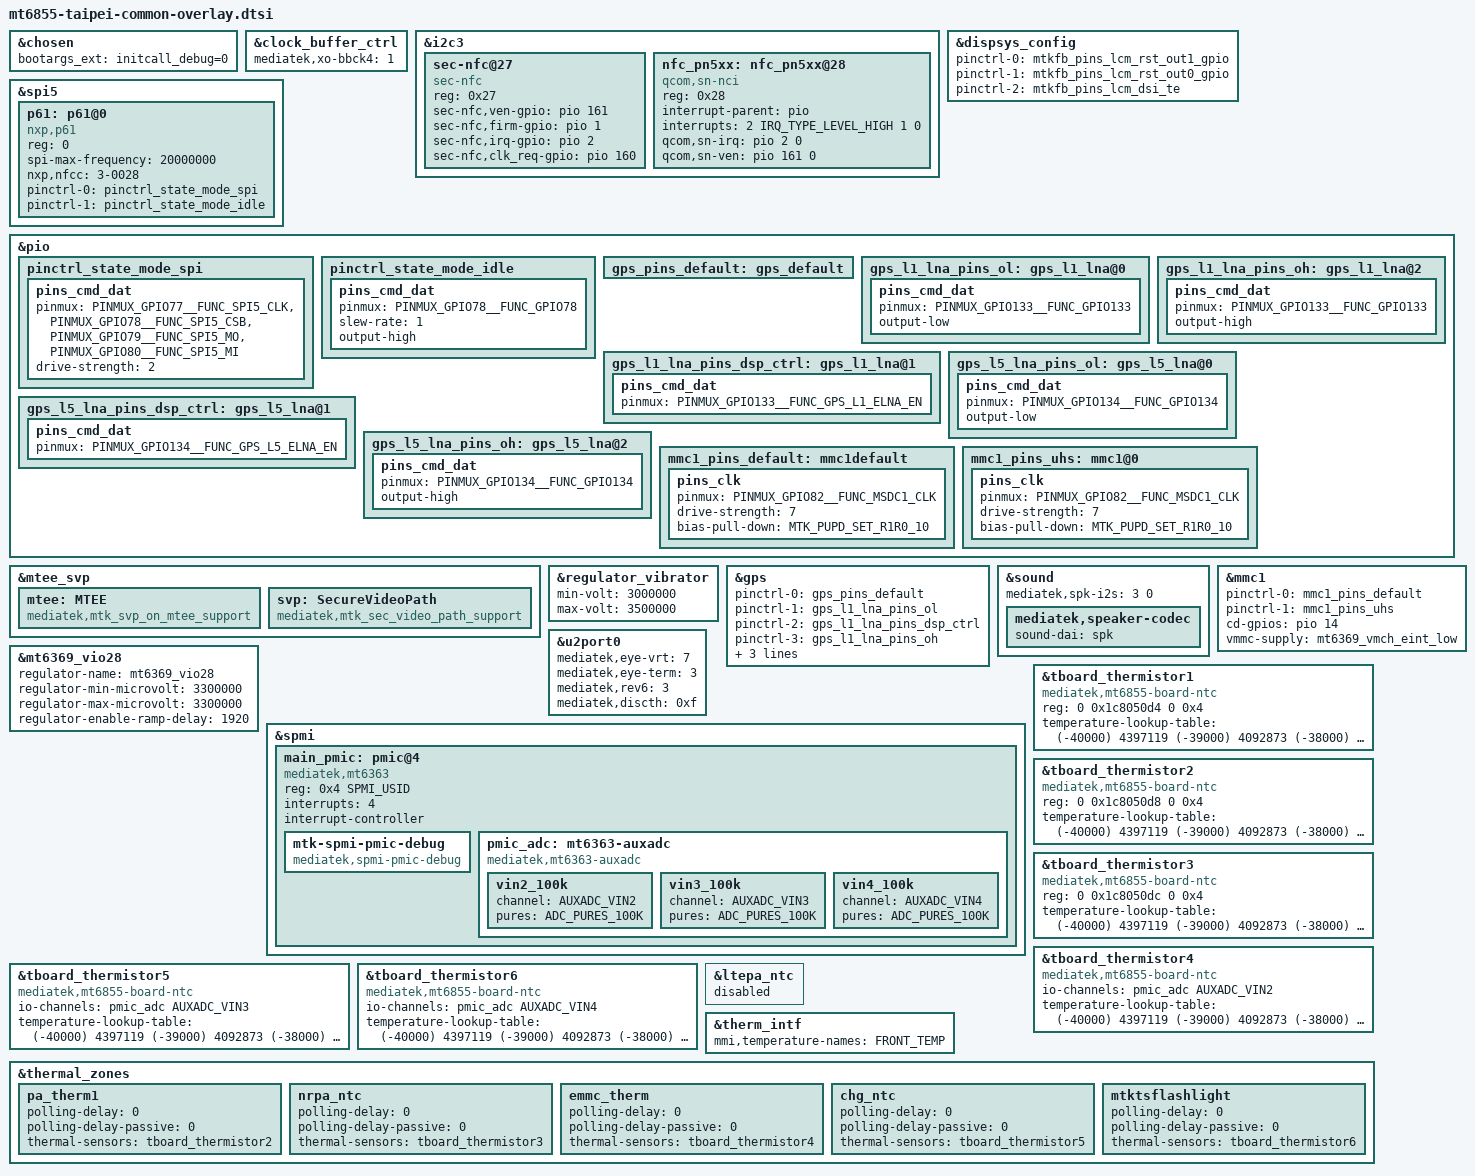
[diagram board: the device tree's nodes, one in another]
/* Copyright (c) 2020, The Linux Foundation. All rights reserved.
 *
 * This program is free software; you can redistribute it and/or modify
 * it under the terms of the GNU General Public License version 2 and
 * only version 2 as published by the Free Software Foundation.
 *
 * This program is distributed in the hope that it will be useful,
 * but WITHOUT ANY WARRANTY; without even the implied warranty of
 * MERCHANTABILITY or FITNESS FOR A PARTICULAR PURPOSE.  See the
 * GNU General Public License for more details.
 */

#include "mediatek/mt6855-moto-common-overlay.dtsi"
#include <dt-bindings/gpio/gpio.h>
#include "mediatek/taipei-display.dtsi"
#include "mediatek/mt6855_taipei_camera_overlay.dtsi"
#include "mediatek/cancunf-sar.dtsi"
#include "mediatek/cancunf-audio.dtsi"
#include "mediatek/mt6855-moto-cancunf-fps.dtsi"
#include "mediatek/mt6855-moto-memory.dtsi"

#include <dt-bindings/iio/mt635x-auxadc.h>
#include <dt-bindings/spmi/spmi.h>

&chosen {
	bootargs_ext = "initcall_debug=0";
};

&clock_buffer_ctrl {
        mediatek,xo-bbck4 = <1>;
};



&i2c3 {
     sec-nfc@27 {
		compatible = "sec-nfc";
		reg = <0x27>;

		sec-nfc,ven-gpio = <&pio 161 0>;
		sec-nfc,firm-gpio = <&pio 1 0>;
		sec-nfc,irq-gpio = <&pio 2 0>;
		sec-nfc,clk_req-gpio = <&pio 160 0>;

		status = "okay";
	};

     nfc_pn5xx: nfc_pn5xx@28 {
		compatible = "qcom,sn-nci";
		reg = <0x28>;
		interrupt-parent = <&pio>;
		interrupts = <2 IRQ_TYPE_LEVEL_HIGH 1 0>;
		qcom,sn-irq = <&pio 2 0>;
		qcom,sn-ven = <&pio 161 0>;
		status = "okay";
	};
};

&dispsys_config {
	pinctrl-names =
		"lcm_rst_out1_gpio", "lcm_rst_out0_gpio",
		"mode_te_te";
	pinctrl-0 = <&mtkfb_pins_lcm_rst_out1_gpio>;
	pinctrl-1 = <&mtkfb_pins_lcm_rst_out0_gpio>;
	pinctrl-2 = <&mtkfb_pins_lcm_dsi_te>;
	status = "okay";
};

&spi5 {
	p61: p61@0 {
		compatible = "nxp,p61";
		reg = <0>;
		spi-max-frequency = <20000000>;
		nxp,nfcc = "3-0028";
//		nxp,p61-rst = <&gpio2 5 0>;
		pinctrl-names = "pinctrl_state_mode_spi",
				"pinctrl_state_mode_idle";
		pinctrl-0 = <&pinctrl_state_mode_spi>;
		pinctrl-1 = <&pinctrl_state_mode_idle>;
		status = "okay";
	};
};

&pio {
        pinctrl_state_mode_spi: pinctrl_state_mode_spi {
                pins_cmd_dat {
                        pinmux = <PINMUX_GPIO77__FUNC_SPI5_CLK>,
                                 <PINMUX_GPIO78__FUNC_SPI5_CSB>,
                                 <PINMUX_GPIO79__FUNC_SPI5_MO>,
                                 <PINMUX_GPIO80__FUNC_SPI5_MI>;
                        drive-strength = <2>;
                };
        };
        pinctrl_state_mode_idle: pinctrl_state_mode_idle {
                pins_cmd_dat {
                        pinmux = <PINMUX_GPIO78__FUNC_GPIO78>;
                        slew-rate = <1>;
                        output-high;
                };
        };
};


/* SVP */
&mtee_svp {
	mtee: MTEE {
		compatible = "mediatek,mtk_svp_on_mtee_support";
	};
	svp: SecureVideoPath {
		compatible = "mediatek,mtk_sec_video_path_support";
	};
};

&regulator_vibrator {
	min-volt = <3000000>;
	max-volt = <3500000>;
	status = "ok";
};

/* GPS GPIO standardization start */
&pio {
	gps_pins_default: gps_default {
	};
	gps_l1_lna_pins_ol: gps_l1_lna@0 {
		pins_cmd_dat {
			pinmux = <PINMUX_GPIO133__FUNC_GPIO133>;
			output-low;
		};
	};
	gps_l1_lna_pins_dsp_ctrl: gps_l1_lna@1 {
		pins_cmd_dat {
			pinmux = <PINMUX_GPIO133__FUNC_GPS_L1_ELNA_EN>;
		};
	};
	gps_l1_lna_pins_oh: gps_l1_lna@2 {
		pins_cmd_dat {
			pinmux = <PINMUX_GPIO133__FUNC_GPIO133>;
			output-high;
		};
	};
	gps_l5_lna_pins_ol: gps_l5_lna@0 {
		pins_cmd_dat {
			pinmux = <PINMUX_GPIO134__FUNC_GPIO134>;
			output-low;
		};
	};
	gps_l5_lna_pins_dsp_ctrl: gps_l5_lna@1 {
		pins_cmd_dat {
			pinmux = <PINMUX_GPIO134__FUNC_GPS_L5_ELNA_EN>;
		};
	};
	gps_l5_lna_pins_oh: gps_l5_lna@2 {
		pins_cmd_dat {
			pinmux = <PINMUX_GPIO134__FUNC_GPIO134>;
			output-high;
		};
	};
};



&gps {
	pinctrl-names = "default",
		"gps_l1_lna_disable",
		"gps_l1_lna_dsp_ctrl",
		"gps_l1_lna_enable",
		"gps_l5_lna_disable",
		"gps_l5_lna_dsp_ctrl",
		"gps_l5_lna_enable";
	pinctrl-0 = <&gps_pins_default>;
	pinctrl-1 = <&gps_l1_lna_pins_ol>;
	pinctrl-2 = <&gps_l1_lna_pins_dsp_ctrl>;
	pinctrl-3 = <&gps_l1_lna_pins_oh>;
	pinctrl-4 = <&gps_l5_lna_pins_ol>;
	pinctrl-5 = <&gps_l5_lna_pins_dsp_ctrl>;
	pinctrl-6 = <&gps_l5_lna_pins_oh>;
	status = "okay";
};
/* GPS GPIO standardization end */

//#include "mediatek/cust_mt6855_touch_1080x2400.dtsi"
#include "mediatek/cust_mt6855_camera_v4l2.dtsi"

/delete-node/ &camera_main_two_af_mtk;

&sound {
	mediatek,spk-i2s = <3 0>;
	mediatek,speaker-codec {
		sound-dai = <&spk>;
	};
};

&mmc1 {
	pinctrl-0 = <&mmc1_pins_default>;
	pinctrl-1 = <&mmc1_pins_uhs>;
	cd-gpios = <&pio 14 GPIO_ACTIVE_HIGH>;
	vmmc-supply = <&mt6369_vmch_eint_low>;
};

&pio {

        mmc1_pins_default: mmc1default {
		pins_clk {
			pinmux = <PINMUX_GPIO82__FUNC_MSDC1_CLK>;
			drive-strength = <7>;
			bias-pull-down = <MTK_PUPD_SET_R1R0_10>;
		};
	};
	mmc1_pins_uhs: mmc1@0{
		pins_clk {
			pinmux = <PINMUX_GPIO82__FUNC_MSDC1_CLK>;
			drive-strength = <7>;
			bias-pull-down = <MTK_PUPD_SET_R1R0_10>;
		};
	};
};

#include "cancunf-touch.dtsi"

//for alsps sensor tmd2755x
&mt6369_vio28 {
	regulator-name = "mt6369_vio28";
	regulator-min-microvolt = <3300000>;
	regulator-max-microvolt = <3300000>;
	regulator-enable-ramp-delay = <1920>;
};

&u2port0{
	mediatek,eye-vrt = <7>;
	mediatek,eye-term = <3>;
	mediatek,rev6 = <3>;
	mediatek,discth = <0xf>;
};


//#include <k6855v1_64/cust.dtsi>
/*End of this file, DO NOT ADD ANYTHING HERE*/
&spmi {
	main_pmic: pmic@4 {
		compatible = "mediatek,mt6363";
		reg = <0x4 SPMI_USID>;
		interrupts = <4>;
		#address-cells = <1>;
		#size-cells = <0>;
		interrupt-controller;
		#interrupt-cells = <2>;

		mtk-spmi-pmic-debug {
			compatible = "mediatek,spmi-pmic-debug";
		};

		pmic_adc: mt6363-auxadc {
			compatible = "mediatek,mt6363-auxadc";
			#io-channel-cells = <1>;
			vin2_100k {
				channel = <AUXADC_VIN2>;
				pures = <ADC_PURES_100K>;
			};
			vin3_100k {
				channel = <AUXADC_VIN3>;
				pures = <ADC_PURES_100K>;
			};
			vin4_100k {
				channel = <AUXADC_VIN4>;
				pures = <ADC_PURES_100K>;
			};
		};

	};
};
&tboard_thermistor1 {
	compatible = "mediatek,mt6855-board-ntc";
	status = "okay";
	#thermal-sensor-cells = <0>;
	reg = <0 0x1c8050d4 0 0x4>; /* TIA DATA T0 */
	temperature-lookup-table = <
		(-40000) 4397119
		(-39000) 4092873
		(-38000) 3811717
		(-37000) 3551748
		(-36000) 3311235
		(-35000) 3088598
		(-34000) 2882395
		(-33000) 2691309
		(-32000) 2514137
		(-31000) 2349777
		(-30000) 2197225
		(-29000) 2055557
		(-28000) 1923931
		(-27000) 1801573
		(-26000) 1687773
		(-25000) 1581880
		(-24000) 1483099
		(-23000) 1391113
		(-22000) 1305412
		(-21000) 1225530
		(-20000) 1151036
		(-19000) 1081535
		(-18000) 1016661
		(-17000) 956079
		(-16000) 899480
		(-15000) 846578
		(-14000) 797111
		(-13000) 750834
		(-12000) 707523
		(-11000) 666972
		(-10000) 628988
		(-9000) 593342
		(-8000) 559930
		(-7000) 528601
		(-6000) 499212
		(-5000) 471632
		(-4000) 445771
		(-3000) 421479
		(-2000) 398652
		(-1000) 377192
		0 357011
		1000 338005
		2000 320121
		3000 303286
		4000 287433
		5000 272499
		6000 258426
		7000 245160
		8000 232649
		9000 220847
		10000 209710
		11000 199196
		12000 189268
		13000 179890
		14000 171027
		15000 162651
		16000 154726
		17000 147232
		18000 140142
		19000 133432
		20000 127080
		21000 121066
		22000 115368
		23000 109970
		24000 104852
		25000 100000
		26000 95398
		27000 91032
		28000 86889
		29000 82956
		30000 79222
		31000 75675
		32000 72306
		33000 69104
		34000 66061
		35000 63167
		36000 60415
		37000 57797
		38000 55306
		39000 52934
		40000 50677
		41000 48528
		42000 46482
		43000 44533
		44000 42675
		45000 40904
		46000 39213
		47000 37601
		48000 36063
		49000 34595
		50000 33195
		51000 31859
		52000 30584
		53000 29366
		54000 28203
		55000 27091
		56000 26028
		57000 25013
		58000 24042
		59000 23113
		60000 22224
		61000 21374
		62000 20560
		63000 19782
		64000 19036
		65000 18322
		66000 17640
		67000 16986
		68000 16360
		69000 15759
		70000 15184
		71000 14631
		72000 14100
		73000 13591
		74000 13103
		75000 12635
		76000 12187
		77000 11756
		78000 11343
		79000 10946
		80000 10565
		81000 10199
		82000 9847
		83000 9509
		84000 9184
		85000 8872
		86000 8572
		87000 8283
		88000 8005
		89000 7738
		90000 7481
		91000 7234
		92000 6997
		93000 6769
		94000 6548
		95000 6337
		96000 6132
		97000 5934
		98000 5744
		99000 5561
		100000 5384
		101000 5214
		102000 5051
		103000 4893
		104000 4741
		105000 4594
		106000 4453
		107000 4316
		108000 4184
		109000 4057
		110000 3934
		111000 3816
		112000 3701
		113000 3591
		114000 3484
		115000 3380
		116000 3281
		117000 3185
		118000 3093
		119000 3003
		120000 2916
		121000 2832
		122000 2751
		123000 2672
		124000 2596
		125000 2522>;
};

&tboard_thermistor2 {
	compatible = "mediatek,mt6855-board-ntc";
	status = "okay";
	#thermal-sensor-cells = <0>;
	reg = <0 0x1c8050d8 0 0x4>; /* TIA DATA T1 */
	temperature-lookup-table = <
		(-40000) 4397119
		(-39000) 4092873
		(-38000) 3811717
		(-37000) 3551748
		(-36000) 3311235
		(-35000) 3088598
		(-34000) 2882395
		(-33000) 2691309
		(-32000) 2514137
		(-31000) 2349777
		(-30000) 2197225
		(-29000) 2055557
		(-28000) 1923931
		(-27000) 1801573
		(-26000) 1687773
		(-25000) 1581880
		(-24000) 1483099
		(-23000) 1391113
		(-22000) 1305412
		(-21000) 1225530
		(-20000) 1151036
		(-19000) 1081535
		(-18000) 1016661
		(-17000) 956079
		(-16000) 899480
		(-15000) 846578
		(-14000) 797111
		(-13000) 750834
		(-12000) 707523
		(-11000) 666972
		(-10000) 628988
		(-9000) 593342
		(-8000) 559930
		(-7000) 528601
		(-6000) 499212
		(-5000) 471632
		(-4000) 445771
		(-3000) 421479
		(-2000) 398652
		(-1000) 377192
		0 357011
		1000 338005
		2000 320121
		3000 303286
		4000 287433
		5000 272499
		6000 258426
		7000 245160
		8000 232649
		9000 220847
		10000 209710
		11000 199196
		12000 189268
		13000 179890
		14000 171027
		15000 162651
		16000 154726
		17000 147232
		18000 140142
		19000 133432
		20000 127080
		21000 121066
		22000 115368
		23000 109970
		24000 104852
		25000 100000
		26000 95398
		27000 91032
		28000 86889
		29000 82956
		30000 79222
		31000 75675
		32000 72306
		33000 69104
		34000 66061
		35000 63167
		36000 60415
		37000 57797
		38000 55306
		39000 52934
		40000 50677
		41000 48528
		42000 46482
		43000 44533
		44000 42675
		45000 40904
		46000 39213
		47000 37601
		48000 36063
		49000 34595
		50000 33195
		51000 31859
		52000 30584
		53000 29366
		54000 28203
		55000 27091
		56000 26028
		57000 25013
		58000 24042
		59000 23113
		60000 22224
		61000 21374
		62000 20560
		63000 19782
		64000 19036
		65000 18322
		66000 17640
		67000 16986
		68000 16360
		69000 15759
		70000 15184
		71000 14631
		72000 14100
		73000 13591
		74000 13103
		75000 12635
		76000 12187
		77000 11756
		78000 11343
		79000 10946
		80000 10565
		81000 10199
		82000 9847
		83000 9509
		84000 9184
		85000 8872
		86000 8572
		87000 8283
		88000 8005
		89000 7738
		90000 7481
		91000 7234
		92000 6997
		93000 6769
		94000 6548
		95000 6337
		96000 6132
		97000 5934
		98000 5744
		99000 5561
		100000 5384
		101000 5214
		102000 5051
		103000 4893
		104000 4741
		105000 4594
		106000 4453
		107000 4316
		108000 4184
		109000 4057
		110000 3934
		111000 3816
		112000 3701
		113000 3591
		114000 3484
		115000 3380
		116000 3281
		117000 3185
		118000 3093
		119000 3003
		120000 2916
		121000 2832
		122000 2751
		123000 2672
		124000 2596
		125000 2522>;
};

&tboard_thermistor3 {
	compatible = "mediatek,mt6855-board-ntc";
	status = "okay";
	#thermal-sensor-cells = <0>;
	reg = <0 0x1c8050dc 0 0x4>; /* TIA DATA T2 */
	temperature-lookup-table = <
		(-40000) 4397119
		(-39000) 4092873
		(-38000) 3811717
		(-37000) 3551748
		(-36000) 3311235
		(-35000) 3088598
		(-34000) 2882395
		(-33000) 2691309
		(-32000) 2514137
		(-31000) 2349777
		(-30000) 2197225
		(-29000) 2055557
		(-28000) 1923931
		(-27000) 1801573
		(-26000) 1687773
		(-25000) 1581880
		(-24000) 1483099
		(-23000) 1391113
		(-22000) 1305412
		(-21000) 1225530
		(-20000) 1151036
		(-19000) 1081535
		(-18000) 1016661
		(-17000) 956079
		(-16000) 899480
		(-15000) 846578
		(-14000) 797111
		(-13000) 750834
		(-12000) 707523
		(-11000) 666972
		(-10000) 628988
		(-9000) 593342
		(-8000) 559930
		(-7000) 528601
		(-6000) 499212
		(-5000) 471632
		(-4000) 445771
		(-3000) 421479
		(-2000) 398652
		(-1000) 377192
		0 357011
		1000 338005
		2000 320121
		3000 303286
		4000 287433
		5000 272499
		6000 258426
		7000 245160
		8000 232649
		9000 220847
		10000 209710
		11000 199196
		12000 189268
		13000 179890
		14000 171027
		15000 162651
		16000 154726
		17000 147232
		18000 140142
		19000 133432
		20000 127080
		21000 121066
		22000 115368
		23000 109970
		24000 104852
		25000 100000
		26000 95398
		27000 91032
		28000 86889
		29000 82956
		30000 79222
		31000 75675
		32000 72306
		33000 69104
		34000 66061
		35000 63167
		36000 60415
		37000 57797
		38000 55306
		39000 52934
		40000 50677
		41000 48528
		42000 46482
		43000 44533
		44000 42675
		45000 40904
		46000 39213
		47000 37601
		48000 36063
		49000 34595
		50000 33195
		51000 31859
		52000 30584
		53000 29366
		54000 28203
		55000 27091
		56000 26028
		57000 25013
		58000 24042
		59000 23113
		60000 22224
		61000 21374
		62000 20560
		63000 19782
		64000 19036
		65000 18322
		66000 17640
		67000 16986
		68000 16360
		69000 15759
		70000 15184
		71000 14631
		72000 14100
		73000 13591
		74000 13103
		75000 12635
		76000 12187
		77000 11756
		78000 11343
		79000 10946
		80000 10565
		81000 10199
		82000 9847
		83000 9509
		84000 9184
		85000 8872
		86000 8572
		87000 8283
		88000 8005
		89000 7738
		90000 7481
		91000 7234
		92000 6997
		93000 6769
		94000 6548
		95000 6337
		96000 6132
		97000 5934
		98000 5744
		99000 5561
		100000 5384
		101000 5214
		102000 5051
		103000 4893
		104000 4741
		105000 4594
		106000 4453
		107000 4316
		108000 4184
		109000 4057
		110000 3934
		111000 3816
		112000 3701
		113000 3591
		114000 3484
		115000 3380
		116000 3281
		117000 3185
		118000 3093
		119000 3003
		120000 2916
		121000 2832
		122000 2751
		123000 2672
		124000 2596
		125000 2522>;
};

&tboard_thermistor4 {
	compatible = "mediatek,mt6855-board-ntc";
	status = "okay";
	#thermal-sensor-cells = <0>;
	io-channels = <&pmic_adc AUXADC_VIN2>;
	io-channel-names = "MD_Thermal_NTC";
	temperature-lookup-table = <
		(-40000) 4397119
		(-39000) 4092873
		(-38000) 3811717
		(-37000) 3551748
		(-36000) 3311235
		(-35000) 3088598
		(-34000) 2882395
		(-33000) 2691309
		(-32000) 2514137
		(-31000) 2349777
		(-30000) 2197225
		(-29000) 2055557
		(-28000) 1923931
		(-27000) 1801573
		(-26000) 1687773
		(-25000) 1581880
		(-24000) 1483099
		(-23000) 1391113
		(-22000) 1305412
		(-21000) 1225530
		(-20000) 1151036
		(-19000) 1081535
		(-18000) 1016661
		(-17000) 956079
		(-16000) 899480
		(-15000) 846578
		(-14000) 797111
		(-13000) 750834
		(-12000) 707523
		(-11000) 666972
		(-10000) 628988
		(-9000) 593342
		(-8000) 559930
		(-7000) 528601
		(-6000) 499212
		(-5000) 471632
		(-4000) 445771
		(-3000) 421479
		(-2000) 398652
		(-1000) 377192
		0 357011
		1000 338005
		2000 320121
		3000 303286
		4000 287433
		5000 272499
		6000 258426
		7000 245160
		8000 232649
		9000 220847
		10000 209710
		11000 199196
		12000 189268
		13000 179890
		14000 171027
		15000 162651
		16000 154726
		17000 147232
		18000 140142
		19000 133432
		20000 127080
		21000 121066
		22000 115368
		23000 109970
		24000 104852
		25000 100000
		26000 95398
		27000 91032
		28000 86889
		29000 82956
		30000 79222
		31000 75675
		32000 72306
		33000 69104
		34000 66061
		35000 63167
		36000 60415
		37000 57797
		38000 55306
		39000 52934
		40000 50677
		41000 48528
		42000 46482
		43000 44533
		44000 42675
		45000 40904
		46000 39213
		47000 37601
		48000 36063
		49000 34595
		50000 33195
		51000 31859
		52000 30584
		53000 29366
		54000 28203
		55000 27091
		56000 26028
		57000 25013
		58000 24042
		59000 23113
		60000 22224
		61000 21374
		62000 20560
		63000 19782
		64000 19036
		65000 18322
		66000 17640
		67000 16986
		68000 16360
		69000 15759
		70000 15184
		71000 14631
		72000 14100
		73000 13591
		74000 13103
		75000 12635
		76000 12187
		77000 11756
		78000 11343
		79000 10946
		80000 10565
		81000 10199
		82000 9847
		83000 9509
		84000 9184
		85000 8872
		86000 8572
		87000 8283
		88000 8005
		89000 7738
		90000 7481
		91000 7234
		92000 6997
		93000 6769
		94000 6548
		95000 6337
		96000 6132
		97000 5934
		98000 5744
		99000 5561
		100000 5384
		101000 5214
		102000 5051
		103000 4893
		104000 4741
		105000 4594
		106000 4453
		107000 4316
		108000 4184
		109000 4057
		110000 3934
		111000 3816
		112000 3701
		113000 3591
		114000 3484
		115000 3380
		116000 3281
		117000 3185
		118000 3093
		119000 3003
		120000 2916
		121000 2832
		122000 2751
		123000 2672
		124000 2596
		125000 2522>;
};

&tboard_thermistor5 {
	compatible = "mediatek,mt6855-board-ntc";
	status = "okay";
	#thermal-sensor-cells = <0>;
	io-channels = <&pmic_adc AUXADC_VIN3>;
	io-channel-names = "Charger_NTC";
	temperature-lookup-table = <
		(-40000) 4397119
		(-39000) 4092873
		(-38000) 3811717
		(-37000) 3551748
		(-36000) 3311235
		(-35000) 3088598
		(-34000) 2882395
		(-33000) 2691309
		(-32000) 2514137
		(-31000) 2349777
		(-30000) 2197225
		(-29000) 2055557
		(-28000) 1923931
		(-27000) 1801573
		(-26000) 1687773
		(-25000) 1581880
		(-24000) 1483099
		(-23000) 1391113
		(-22000) 1305412
		(-21000) 1225530
		(-20000) 1151036
		(-19000) 1081535
		(-18000) 1016661
		(-17000) 956079
		(-16000) 899480
		(-15000) 846578
		(-14000) 797111
		(-13000) 750834
		(-12000) 707523
		(-11000) 666972
		(-10000) 628988
		(-9000) 593342
		(-8000) 559930
		(-7000) 528601
		(-6000) 499212
		(-5000) 471632
		(-4000) 445771
		(-3000) 421479
		(-2000) 398652
		(-1000) 377192
		0 357011
		1000 338005
		2000 320121
		3000 303286
		4000 287433
		5000 272499
		6000 258426
		7000 245160
		8000 232649
		9000 220847
		10000 209710
		11000 199196
		12000 189268
		13000 179890
		14000 171027
		15000 162651
		16000 154726
		17000 147232
		18000 140142
		19000 133432
		20000 127080
		21000 121066
		22000 115368
		23000 109970
		24000 104852
		25000 100000
		26000 95398
		27000 91032
		28000 86889
		29000 82956
		30000 79222
		31000 75675
		32000 72306
		33000 69104
		34000 66061
		35000 63167
		36000 60415
		37000 57797
		38000 55306
		39000 52934
		40000 50677
		41000 48528
		42000 46482
		43000 44533
		44000 42675
		45000 40904
		46000 39213
		47000 37601
		48000 36063
		49000 34595
		50000 33195
		51000 31859
		52000 30584
		53000 29366
		54000 28203
		55000 27091
		56000 26028
		57000 25013
		58000 24042
		59000 23113
		60000 22224
		61000 21374
		62000 20560
		63000 19782
		64000 19036
		65000 18322
		66000 17640
		67000 16986
		68000 16360
		69000 15759
		70000 15184
		71000 14631
		72000 14100
		73000 13591
		74000 13103
		75000 12635
		76000 12187
		77000 11756
		78000 11343
		79000 10946
		80000 10565
		81000 10199
		82000 9847
		83000 9509
		84000 9184
		85000 8872
		86000 8572
		87000 8283
		88000 8005
		89000 7738
		90000 7481
		91000 7234
		92000 6997
		93000 6769
		94000 6548
		95000 6337
		96000 6132
		97000 5934
		98000 5744
		99000 5561
		100000 5384
		101000 5214
		102000 5051
		103000 4893
		104000 4741
		105000 4594
		106000 4453
		107000 4316
		108000 4184
		109000 4057
		110000 3934
		111000 3816
		112000 3701
		113000 3591
		114000 3484
		115000 3380
		116000 3281
		117000 3185
		118000 3093
		119000 3003
		120000 2916
		121000 2832
		122000 2751
		123000 2672
		124000 2596
		125000 2522>;
};

&tboard_thermistor6 {
	compatible = "mediatek,mt6855-board-ntc";
	status = "okay";
	#thermal-sensor-cells = <0>;
	io-channels = <&pmic_adc AUXADC_VIN4>;
	io-channel-names = "Flash_LED_NTC";
	temperature-lookup-table = <
		(-40000) 4397119
		(-39000) 4092873
		(-38000) 3811717
		(-37000) 3551748
		(-36000) 3311235
		(-35000) 3088598
		(-34000) 2882395
		(-33000) 2691309
		(-32000) 2514137
		(-31000) 2349777
		(-30000) 2197225
		(-29000) 2055557
		(-28000) 1923931
		(-27000) 1801573
		(-26000) 1687773
		(-25000) 1581880
		(-24000) 1483099
		(-23000) 1391113
		(-22000) 1305412
		(-21000) 1225530
		(-20000) 1151036
		(-19000) 1081535
		(-18000) 1016661
		(-17000) 956079
		(-16000) 899480
		(-15000) 846578
		(-14000) 797111
		(-13000) 750834
		(-12000) 707523
		(-11000) 666972
		(-10000) 628988
		(-9000) 593342
		(-8000) 559930
		(-7000) 528601
		(-6000) 499212
		(-5000) 471632
		(-4000) 445771
		(-3000) 421479
		(-2000) 398652
		(-1000) 377192
		0 357011
		1000 338005
		2000 320121
		3000 303286
		4000 287433
		5000 272499
		6000 258426
		7000 245160
		8000 232649
		9000 220847
		10000 209710
		11000 199196
		12000 189268
		13000 179890
		14000 171027
		15000 162651
		16000 154726
		17000 147232
		18000 140142
		19000 133432
		20000 127080
		21000 121066
		22000 115368
		23000 109970
		24000 104852
		25000 100000
		26000 95398
		27000 91032
		28000 86889
		29000 82956
		30000 79222
		31000 75675
		32000 72306
		33000 69104
		34000 66061
		35000 63167
		36000 60415
		37000 57797
		38000 55306
		39000 52934
		40000 50677
		41000 48528
		42000 46482
		43000 44533
		44000 42675
		45000 40904
		46000 39213
		47000 37601
		48000 36063
		49000 34595
		50000 33195
		51000 31859
		52000 30584
		53000 29366
		54000 28203
		55000 27091
		56000 26028
		57000 25013
		58000 24042
		59000 23113
		60000 22224
		61000 21374
		62000 20560
		63000 19782
		64000 19036
		65000 18322
		66000 17640
		67000 16986
		68000 16360
		69000 15759
		70000 15184
		71000 14631
		72000 14100
		73000 13591
		74000 13103
		75000 12635
		76000 12187
		77000 11756
		78000 11343
		79000 10946
		80000 10565
		81000 10199
		82000 9847
		83000 9509
		84000 9184
		85000 8872
		86000 8572
		87000 8283
		88000 8005
		89000 7738
		90000 7481
		91000 7234
		92000 6997
		93000 6769
		94000 6548
		95000 6337
		96000 6132
		97000 5934
		98000 5744
		99000 5561
		100000 5384
		101000 5214
		102000 5051
		103000 4893
		104000 4741
		105000 4594
		106000 4453
		107000 4316
		108000 4184
		109000 4057
		110000 3934
		111000 3816
		112000 3701
		113000 3591
		114000 3484
		115000 3380
		116000 3281
		117000 3185
		118000 3093
		119000 3003
		120000 2916
		121000 2832
		122000 2751
		123000 2672
		124000 2596
		125000 2522>;
};

&ltepa_ntc {
	status = "disabled";
};

&therm_intf {
	/*Vsensor name should be CASE DIFFERENT with the name in config file*/
	mmi,temperature-names = "FRONT_TEMP";/*for "front_temp" in config file*/
};

&thermal_zones{
//		ap_ntc: ap_ntc {
//			polling-delay = <0>; /* milliseconds */
//			polling-delay-passive = <0>; /* milliseconds */
//			thermal-sensors = <&tboard_thermistor1>;
//		};
		pa_therm1: pa_therm1 {
			polling-delay = <0>; /* milliseconds */
			polling-delay-passive = <0>; /* milliseconds */
			thermal-sensors = <&tboard_thermistor2>;
		};
		nrpa_ntc: nrpa_ntc {
			polling-delay = <0>; /* milliseconds */
			polling-delay-passive = <0>; /* milliseconds */
			thermal-sensors = <&tboard_thermistor3>;
		};
//		chg_ntc {
//			polling-delay = <0>; /* milliseconds */
//			polling-delay-passive = <0>; /* milliseconds */
//			thermal-sensors = <&tboard_thermistor4>;
//		};
		emmc_therm {
			polling-delay = <0>; /* milliseconds */
			polling-delay-passive = <0>; /* milliseconds */
			thermal-sensors = <&tboard_thermistor4>;
		};
		chg_ntc {
			polling-delay = <0>; /* milliseconds */
			polling-delay-passive = <0>; /* milliseconds */
			thermal-sensors = <&tboard_thermistor5>;
		};
		mtktsflashlight {
			polling-delay = <0>; /* milliseconds */
			polling-delay-passive = <0>; /* milliseconds */
			thermal-sensors = <&tboard_thermistor6>;
		};
};
